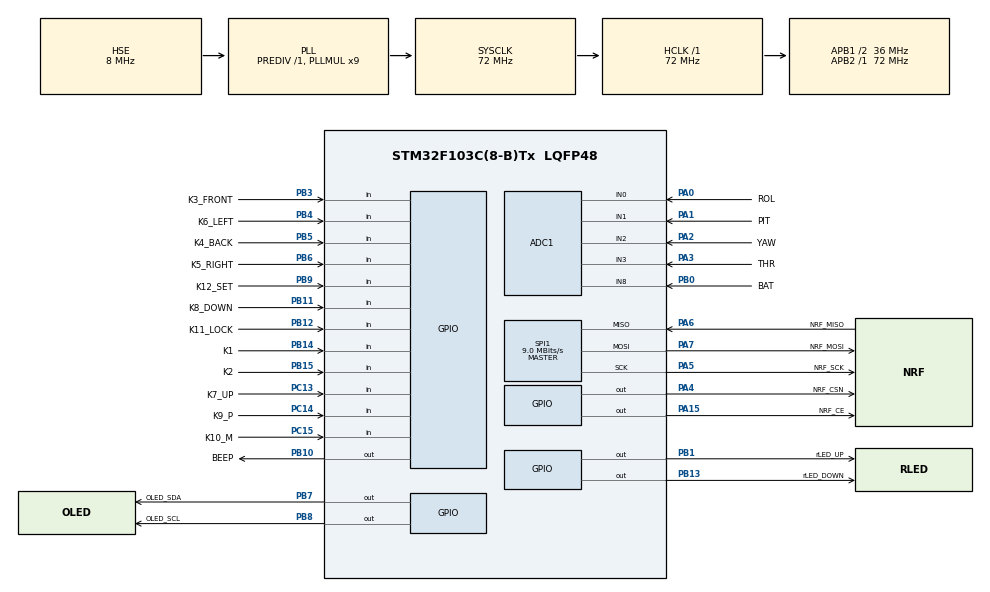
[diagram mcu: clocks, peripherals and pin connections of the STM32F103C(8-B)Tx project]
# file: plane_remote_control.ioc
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ADC1.Channel-0\#ChannelRegularConversion=ADC_CHANNEL_0
ADC1.Channel-1\#ChannelRegularConversion=ADC_CHANNEL_1
ADC1.Channel-2\#ChannelRegularConversion=ADC_CHANNEL_2
ADC1.Channel-3\#ChannelRegularConversion=ADC_CHANNEL_3
ADC1.Channel-4\#ChannelRegularConversion=ADC_CHANNEL_8
ADC1.Channel-5\#ChannelRegularConversion=ADC_CHANNEL_VREFINT
ADC1.ContinuousConvMode=ENABLE
ADC1.DataAlign=ADC_DATAALIGN_RIGHT
ADC1.NbrOfConversion=6
ADC1.NbrOfConversionFlag=1
ADC1.Rank-0\#ChannelRegularConversion=1
ADC1.Rank-1\#ChannelRegularConversion=2
ADC1.Rank-2\#ChannelRegularConversion=3
ADC1.Rank-3\#ChannelRegularConversion=4
ADC1.Rank-4\#ChannelRegularConversion=5
ADC1.Rank-5\#ChannelRegularConversion=6
ADC1.SamplingTime-0\#ChannelRegularConversion=ADC_SAMPLETIME_71CYCLES_5
ADC1.SamplingTime-1\#ChannelRegularConversion=ADC_SAMPLETIME_71CYCLES_5
ADC1.SamplingTime-2\#ChannelRegularConversion=ADC_SAMPLETIME_71CYCLES_5
ADC1.SamplingTime-3\#ChannelRegularConversion=ADC_SAMPLETIME_239CYCLES_5
ADC1.SamplingTime-4\#ChannelRegularConversion=ADC_SAMPLETIME_71CYCLES_5
ADC1.SamplingTime-5\#ChannelRegularConversion=ADC_SAMPLETIME_239CYCLES_5
ADC1.master=1
Dma.ADC1.0.Direction=DMA_PERIPH_TO_MEMORY
Dma.ADC1.0.Instance=DMA1_Channel1
Dma.ADC1.0.MemDataAlignment=DMA_MDATAALIGN_HALFWORD
Dma.ADC1.0.MemInc=DMA_MINC_ENABLE
Dma.ADC1.0.Mode=DMA_CIRCULAR
Dma.ADC1.0.PeriphDataAlignment=DMA_PDATAALIGN_HALFWORD
Dma.ADC1.0.PeriphInc=DMA_PINC_DISABLE
Dma.ADC1.0.Priority=DMA_PRIORITY_HIGH
Dma.Request0=ADC1
FREERTOS.Tasks01=defaultTask,0,128,StartDefaultTask,Default,NULL,Dynamic,NULL,NULL
Mcu.Family=STM32F1
Mcu.Name=STM32F103C(8-B)Tx
Mcu.Package=LQFP48
NVIC.DMA1_Channel1_IRQn=true\:5\:0\:false\:false\:true\:true\:false\:true\:true
NVIC.PriorityGroup=NVIC_PRIORITYGROUP_4
NVIC.TIM4_IRQn=true\:15\:0\:false\:false\:true\:false\:false\:true\:true
NVIC.TimeBase=TIM4_IRQn
NVIC.TimeBaseIP=TIM4
PA0-WKUP.GPIO_Label=ROL
PA0-WKUP.Signal=ADCx_IN0
PA1.GPIO_Label=PIT
PA1.Signal=ADCx_IN1
PA13.Mode=Serial_Wire
PA13.Signal=SYS_JTMS-SWDIO
PA14.Mode=Serial_Wire
PA14.Signal=SYS_JTCK-SWCLK
PA15.GPIO_Label=NRF_CE
PA15.GPIO_Speed=GPIO_SPEED_FREQ_HIGH
PA15.PinState=GPIO_PIN_SET
PA15.Signal=GPIO_Output
PA2.GPIO_Label=YAW
PA2.Signal=ADCx_IN2
PA3.GPIO_Label=THR
PA3.Signal=ADCx_IN3
PA4.GPIO_Label=NRF_CSN
PA4.GPIO_Speed=GPIO_SPEED_FREQ_HIGH
PA4.PinState=GPIO_PIN_SET
PA4.Signal=GPIO_Output
PA5.GPIO_Label=NRF_SCK
PA5.Mode=Full_Duplex_Master
PA5.Signal=SPI1_SCK
PA6.GPIO_Label=NRF_MISO
PA6.GPIO_PuPd=GPIO_PULLUP
PA6.Mode=Full_Duplex_Master
PA6.Signal=SPI1_MISO
PA7.GPIO_Label=NRF_MOSI
PA7.Mode=Full_Duplex_Master
PA7.Signal=SPI1_MOSI
PB0.GPIO_Label=BAT
PB0.Signal=ADCx_IN8
PB1.GPIO_Label=rLED_UP
PB1.GPIO_Speed=GPIO_SPEED_FREQ_HIGH
PB1.PinState=GPIO_PIN_SET
PB1.Signal=GPIO_Output
PB10.GPIO_Label=BEEP
PB10.PinState=GPIO_PIN_SET
PB10.Signal=GPIO_Output
PB11.GPIO_Label=K8_DOWN
PB11.GPIO_PuPd=GPIO_PULLUP
PB11.Signal=GPIO_Input
PB12.GPIO_Label=K11_LOCK
PB12.GPIO_PuPd=GPIO_PULLUP
PB12.Signal=GPIO_Input
PB13.GPIO_Label=rLED_DOWN
PB13.GPIO_Speed=GPIO_SPEED_FREQ_HIGH
PB13.PinState=GPIO_PIN_SET
PB13.Signal=GPIO_Output
PB14.GPIO_Label=K1
PB14.GPIO_PuPd=GPIO_PULLUP
PB14.Signal=GPIO_Input
PB15.GPIO_Label=K2
PB15.GPIO_PuPd=GPIO_PULLUP
PB15.Signal=GPIO_Input
PB3.GPIO_Label=K3_FRONT
PB3.GPIO_PuPd=GPIO_PULLUP
PB3.Signal=GPIO_Input
PB4.GPIO_Label=K6_LEFT
PB4.GPIO_PuPd=GPIO_PULLUP
PB4.Signal=GPIO_Input
PB5.GPIO_Label=K4_BACK
PB5.GPIO_PuPd=GPIO_PULLUP
PB5.Signal=GPIO_Input
PB6.GPIO_Label=K5_RIGHT
PB6.GPIO_PuPd=GPIO_PULLUP
PB6.Signal=GPIO_Input
PB7.GPIO_Label=OLED_SDA
PB7.GPIO_ModeDefaultOutputPP=GPIO_MODE_OUTPUT_OD
PB7.GPIO_PuPd=GPIO_PULLUP
PB7.GPIO_Speed=GPIO_SPEED_FREQ_HIGH
PB7.PinState=GPIO_PIN_SET
PB7.Signal=GPIO_Output
PB8.GPIO_Label=OLED_SCL
PB8.GPIO_ModeDefaultOutputPP=GPIO_MODE_OUTPUT_OD
PB8.GPIO_PuPd=GPIO_PULLUP
PB8.GPIO_Speed=GPIO_SPEED_FREQ_HIGH
PB8.PinState=GPIO_PIN_SET
PB8.Signal=GPIO_Output
PB9.GPIO_Label=K12_SET
PB9.GPIO_PuPd=GPIO_PULLUP
PB9.Signal=GPIO_Input
PC13-TAMPER-RTC.GPIO_Label=K7_UP
PC13-TAMPER-RTC.GPIO_PuPd=GPIO_PULLUP
PC13-TAMPER-RTC.Signal=GPIO_Input
PC14-OSC32_IN.GPIO_Label=K9_P
PC14-OSC32_IN.GPIO_PuPd=GPIO_PULLUP
PC14-OSC32_IN.Signal=GPIO_Input
PC15-OSC32_OUT.GPIO_Label=K10_M
PC15-OSC32_OUT.GPIO_PuPd=GPIO_PULLUP
PC15-OSC32_OUT.Signal=GPIO_Input
PD0-OSC_IN.Mode=HSE-External-Oscillator
PD0-OSC_IN.Signal=RCC_OSC_IN
PD1-OSC_OUT.Mode=HSE-External-Oscillator
PD1-OSC_OUT.Signal=RCC_OSC_OUT
ProjectManager.HeapSize=0x200
ProjectManager.StackSize=0x400
ProjectManager.TargetToolchain=CMake
RCC.ADCPresc=RCC_ADCPCLK2_DIV6
RCC.AHBFreq_Value=72000000
RCC.APB1CLKDivider=RCC_HCLK_DIV2
RCC.APB1Freq_Value=36000000
RCC.APB1TimFreq_Value=72000000
RCC.APB2Freq_Value=72000000
RCC.APB2TimFreq_Value=72000000
RCC.HCLKFreq_Value=72000000
RCC.PLLMUL=RCC_PLL_MUL9
RCC.PLLSourceVirtual=RCC_PLLSOURCE_HSE
RCC.SYSCLKFreq_VALUE=72000000
RCC.SYSCLKSource=RCC_SYSCLKSOURCE_PLLCLK
RCC.USBFreq_Value=72000000
SH.ADCx_IN0.0=ADC1_IN0,IN0
SH.ADCx_IN1.0=ADC1_IN1,IN1
SH.ADCx_IN2.0=ADC1_IN2,IN2
SH.ADCx_IN3.0=ADC1_IN3,IN3
SH.ADCx_IN8.0=ADC1_IN8,IN8
SPI1.BaudRatePrescaler=SPI_BAUDRATEPRESCALER_8
SPI1.CalculateBaudRate=9.0 MBits/s
SPI1.Direction=SPI_DIRECTION_2LINES
SPI1.Mode=SPI_MODE_MASTER
SPI1.VirtualType=VM_MASTER
VP_ADC1_Vref_Input.Mode=IN-Vrefint
VP_FREERTOS_VS_CMSIS_V1.Mode=CMSIS_V1
VP_SYS_VS_tim4.Mode=TIM4
board=custom

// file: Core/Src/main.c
/* USER CODE BEGIN Header */
/**
  ******************************************************************************
  * @file           : main.c
  * @brief          : Main program body
  ******************************************************************************
  * @attention
  *
  * Copyright (c) 2026 STMicroelectronics.
  * All rights reserved.
  *
  * This software is licensed under terms that can be found in the LICENSE file
  * in the root directory of this software component.
  * If no LICENSE file comes with this software, it is provided AS-IS.
  *
  ******************************************************************************
  */
/* USER CODE END Header */
#include "main.h"
#include "cmsis_os.h"
#include "adc.h"
#include "dma.h"
#include "spi.h"
#include "gpio.h"

/* USER CODE BEGIN Includes */
#include "headfile.h"
#include "stm32f1xx_hal.h"
/* USER CODE END Includes */

void SystemClock_Config(void);
void MX_FREERTOS_Init(void);

int main(void)
{

  /* MCU Configuration--------------------------------------------------------*/

  /* Reset of all peripherals, Initializes the Flash interface and the Systick. */
  HAL_Init();

  /* Configure the system clock */
  SystemClock_Config();

  /* Initialize all configured peripherals */
  MX_GPIO_Init();
  MX_DMA_Init();
  MX_SPI1_Init();
  MX_ADC1_Init();
  /* USER CODE BEGIN 2 */
  System_Init();
  /* USER CODE END 2 */

  /* Call init function for freertos objects (in cmsis_os2.c) */
  MX_FREERTOS_Init();

  /* Start scheduler */
  osKernelStart();

  /* We should never get here as control is now taken by the scheduler */

  /* Infinite loop */
  while (1)
  {

  }
}

void SystemClock_Config(void)
{
  RCC_OscInitTypeDef RCC_OscInitStruct = {0};
  RCC_ClkInitTypeDef RCC_ClkInitStruct = {0};
  RCC_PeriphCLKInitTypeDef PeriphClkInit = {0};

  /** Initializes the RCC Oscillators according to the specified parameters
  * in the RCC_OscInitTypeDef structure.
  */
  RCC_OscInitStruct.OscillatorType = RCC_OSCILLATORTYPE_HSE;
  RCC_OscInitStruct.HSEState = RCC_HSE_ON;
  RCC_OscInitStruct.HSEPredivValue = RCC_HSE_PREDIV_DIV1;
  RCC_OscInitStruct.HSIState = RCC_HSI_ON;
  RCC_OscInitStruct.PLL.PLLState = RCC_PLL_ON;
  RCC_OscInitStruct.PLL.PLLSource = RCC_PLLSOURCE_HSE;
  RCC_OscInitStruct.PLL.PLLMUL = RCC_PLL_MUL9;
  if (HAL_RCC_OscConfig(&RCC_OscInitStruct) != HAL_OK)
  {
    Error_Handler();
  }

  /** Initializes the CPU, AHB and APB buses clocks
  */
  RCC_ClkInitStruct.ClockType = RCC_CLOCKTYPE_HCLK|RCC_CLOCKTYPE_SYSCLK
                              |RCC_CLOCKTYPE_PCLK1|RCC_CLOCKTYPE_PCLK2;
  RCC_ClkInitStruct.SYSCLKSource = RCC_SYSCLKSOURCE_PLLCLK;
  RCC_ClkInitStruct.AHBCLKDivider = RCC_SYSCLK_DIV1;
  RCC_ClkInitStruct.APB1CLKDivider = RCC_HCLK_DIV2;
  RCC_ClkInitStruct.APB2CLKDivider = RCC_HCLK_DIV1;

  if (HAL_RCC_ClockConfig(&RCC_ClkInitStruct, FLASH_LATENCY_2) != HAL_OK)
  {
    Error_Handler();
  }
  PeriphClkInit.PeriphClockSelection = RCC_PERIPHCLK_ADC;
  PeriphClkInit.AdcClockSelection = RCC_ADCPCLK2_DIV6;
  if (HAL_RCCEx_PeriphCLKConfig(&PeriphClkInit) != HAL_OK)
  {
    Error_Handler();
  }
}

void HAL_TIM_PeriodElapsedCallback(TIM_HandleTypeDef *htim)
{
  if (htim->Instance == TIM4)
  {
    HAL_IncTick();
  }
}

void Error_Handler(void)
{
  __disable_irq();
  while (1)
  {
  }
}

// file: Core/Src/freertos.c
/* USER CODE BEGIN Header */
/**
  ******************************************************************************
  * File Name          : freertos.c
  * Description        : Code for freertos applications
  ******************************************************************************
  * @attention
  *
  * Copyright (c) 2026 STMicroelectronics.
  * All rights reserved.
  *
  * This software is licensed under terms that can be found in the LICENSE file
  * in the root directory of this software component.
  * If no LICENSE file comes with this software, it is provided AS-IS.
  *
  ******************************************************************************
  */
/* USER CODE END Header */

#include "FreeRTOS.h"
#include "task.h"
#include "main.h"
#include "cmsis_os.h"

// osThreadId stickTaskHandle;
osThreadId commTaskHandle;
osThreadId keyTaskHandle;
osThreadId showTaskHandle;

void StartDefaultTask(void const * argument);

void MX_FREERTOS_Init(void); /* (MISRA C 2004 rule 8.1) */

/* GetIdleTaskMemory prototype (linked to static allocation support) */
void vApplicationGetIdleTaskMemory( StaticTask_t **ppxIdleTaskTCBBuffer, StackType_t **ppxIdleTaskStackBuffer, uint32_t *pulIdleTaskStackSize );

/* USER CODE BEGIN GET_IDLE_TASK_MEMORY */
static StaticTask_t xIdleTaskTCBBuffer;
static StackType_t xIdleStack[configMINIMAL_STACK_SIZE];

void vApplicationGetIdleTaskMemory( StaticTask_t **ppxIdleTaskTCBBuffer, StackType_t **ppxIdleTaskStackBuffer, uint32_t *pulIdleTaskStackSize )
{
  *ppxIdleTaskTCBBuffer = &xIdleTaskTCBBuffer;
  *ppxIdleTaskStackBuffer = &xIdleStack[0];
  *pulIdleTaskStackSize = configMINIMAL_STACK_SIZE;
  /* place for user code */
}
/* USER CODE END GET_IDLE_TASK_MEMORY */

void MX_FREERTOS_Init(void) {

  /* Create the thread(s) */
  /* definition and creation of defaultTask */
  // osThreadDef(stickTask, StartStickTask, osPriorityRealtime, 0, 128);
  // stickTaskHandle = osThreadCreate(osThread(stickTask), NULL);

  osThreadDef(commonTask, StartCommonTask, osPriorityRealtime, 0, 256);
  commTaskHandle = osThreadCreate(osThread(commonTask), NULL);

  osThreadDef(keyTask, StartKeyTask, osPriorityHigh, 0, 128);
  keyTaskHandle = osThreadCreate(osThread(keyTask), NULL);

  osThreadDef(showTask, StartShowTask, osPriorityHigh, 0, 256);
  showTaskHandle = osThreadCreate(osThread(showTask), NULL);

  // osThreadDef(ledTask, StartLedTask, osPriorityNormal, 0, 128);
  // ledTaskHandle = osThreadCreate(osThread(ledTask), NULL);

}

void StartDefaultTask(void const * argument)
{
  for(;;)
  {
    osDelay(1);
  }
}
